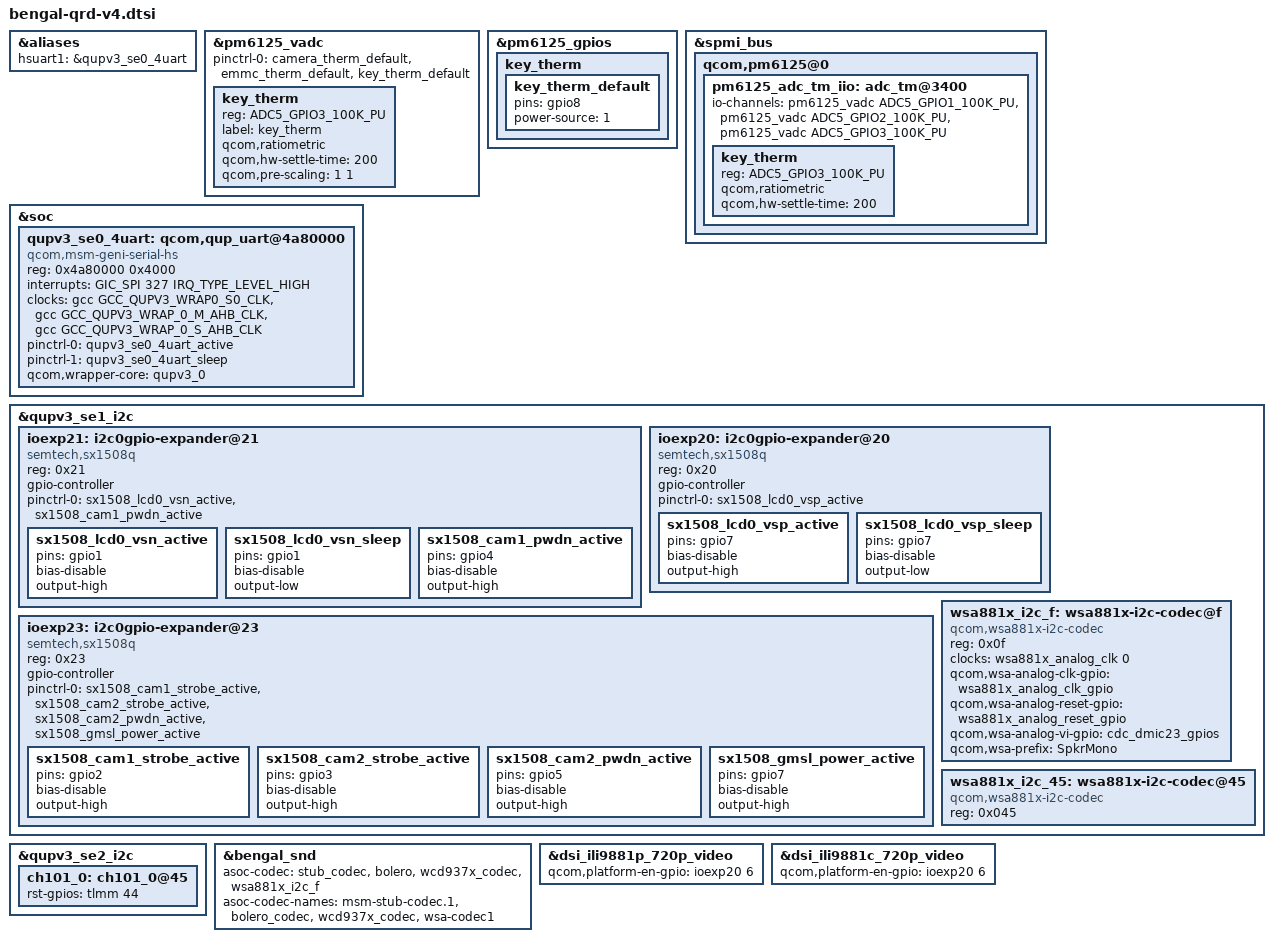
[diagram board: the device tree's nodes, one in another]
// SPDX-License-Identifier: BSD-3-Clause
/*
 * Copyright (c) Qualcomm Technologies, Inc. and/or its subsidiaries.
 */

#include "bengal-qrd-v3.dtsi"

&aliases {
	hsuart1 = &qupv3_se0_4uart;
};

&pm6125_vadc {
	pinctrl-0 = <&camera_therm_default &emmc_therm_default &key_therm_default>;

	key_therm {
		reg = <ADC5_GPIO3_100K_PU>;
		label = "key_therm";
		qcom,ratiometric;
		qcom,hw-settle-time = <200>;
		qcom,pre-scaling = <1 1>;
	};
};

&pm6125_gpios {
	key_therm {
		key_therm_default: key_therm_default {
			pins = "gpio8";
			power-source = <1>;
		};
	};

};

&spmi_bus {
	qcom,pm6125@0 {
		pm6125_adc_tm_iio: adc_tm@3400 {
			/delete-property/ io-channels;
			io-channels = <&pm6125_vadc ADC5_GPIO1_100K_PU>,
					<&pm6125_vadc ADC5_GPIO2_100K_PU>,
					<&pm6125_vadc ADC5_GPIO3_100K_PU>;

			key_therm {
				reg = <ADC5_GPIO3_100K_PU>;
				qcom,ratiometric;
				qcom,hw-settle-time = <200>;
			};
		};
	};
};

&soc {
	/delete-node/ i2c@4a80000;

	qupv3_se0_4uart: qcom,qup_uart@4a80000 {
		compatible = "qcom,msm-geni-serial-hs";
		reg = <0x4a80000 0x4000>;
		reg-names = "se_phys";
		interrupts = <GIC_SPI 327 IRQ_TYPE_LEVEL_HIGH>;
		clock-names = "se-clk", "m-ahb", "s-ahb";
		clocks = <&gcc GCC_QUPV3_WRAP0_S0_CLK>,
			<&gcc GCC_QUPV3_WRAP_0_M_AHB_CLK>,
			<&gcc GCC_QUPV3_WRAP_0_S_AHB_CLK>;
		pinctrl-names = "default", "sleep";
		pinctrl-0 = <&qupv3_se0_4uart_active>;
		pinctrl-1 = <&qupv3_se0_4uart_sleep>;
		qcom,wrapper-core = <&qupv3_0>;
		status = "ok";
	};
};

&qupv3_se1_i2c {
	status = "ok";

	ioexp21: i2c0gpio-expander@21 {
		#gpio-cells = <2>;
		compatible = "semtech,sx1508q";
		reg = <0x21>;
		gpio-controller;

		pinctrl-names = "default";
		pinctrl-0 = <&sx1508_lcd0_vsn_active
				&sx1508_cam1_pwdn_active>;

		sx1508_lcd0_vsn_active: sx1508_lcd0_vsn_active {
			pins = "gpio1";
			bias-disable;
			output-high;
		};

		sx1508_lcd0_vsn_sleep: sx1508_lcd0_vsn_sleep {
			pins = "gpio1";
			bias-disable;
			output-low;
		};

		sx1508_cam1_pwdn_active: sx1508_cam1_pwdn_active {
			pins = "gpio4";
			bias-disable;
			output-high;
		};
	};

	ioexp20: i2c0gpio-expander@20 {
		#gpio-cells = <2>;
		compatible = "semtech,sx1508q";
		reg = <0x20>;
		gpio-controller;

		pinctrl-names = "default";
		pinctrl-0 = <&sx1508_lcd0_vsp_active>;

		sx1508_lcd0_vsp_active: sx1508_lcd0_vsp_active {
			pins = "gpio7";
			bias-disable;
			output-high;
		};

		sx1508_lcd0_vsp_sleep: sx1508_lcd0_vsp_sleep {
			pins = "gpio7";
			bias-disable;
			output-low;
		};
	};

	ioexp23: i2c0gpio-expander@23 {
		#gpio-cells = <2>;
		compatible = "semtech,sx1508q";
		reg = <0x23>;
		gpio-controller;

		pinctrl-names = "default";
		pinctrl-0 = <&sx1508_cam1_strobe_active
				&sx1508_cam2_strobe_active
				&sx1508_cam2_pwdn_active
				&sx1508_gmsl_power_active>;

		sx1508_cam1_strobe_active: sx1508_cam1_strobe_active {
			pins = "gpio2";
			bias-disable;
			output-high;
		};

		sx1508_cam2_strobe_active: sx1508_cam2_strobe_active {
			pins = "gpio3";
			bias-disable;
			output-high;
		};

		sx1508_cam2_pwdn_active: sx1508_cam2_pwdn_active {
			pins = "gpio5";
			bias-disable;
			output-high;
		};

		sx1508_gmsl_power_active: sx1508_gmsl_power_active {
			pins = "gpio7";
			bias-disable;
			output-high;
		};
	};
};

&qupv3_se2_i2c {
	ch101_0: ch101_0@45 {
		/delete-property/ rst-gpios;
		rst-gpios = <&tlmm 44 GPIO_ACTIVE_HIGH>;
	};
};

&bengal_snd {
	/delete-property/ asoc-codec;
	/delete-property/ asoc-codec-names;
	asoc-codec  = <&stub_codec>, <&bolero>,
			<&wcd937x_codec>, <&wsa881x_i2c_f>;
	asoc-codec-names = "msm-stub-codec.1", "bolero_codec",
		"wcd937x_codec", "wsa-codec1";

};

&qupv3_se1_i2c {
	/delete-node/ wsa881x-i2c-codec@e;
	wsa881x_i2c_f: wsa881x-i2c-codec@f {
		compatible = "qcom,wsa881x-i2c-codec";
		reg = <0x0f>;
		clock-names = "wsa_mclk";
		clocks = <&wsa881x_analog_clk 0>;
		qcom,wsa-analog-clk-gpio = <&wsa881x_analog_clk_gpio>;
		qcom,wsa-analog-reset-gpio = <&wsa881x_analog_reset_gpio>;
		qcom,wsa-analog-vi-gpio = <&cdc_dmic23_gpios>;
		qcom,wsa-prefix = "SpkrMono";
	};

	/delete-node/ wsa881x-i2c-codec@44;
	wsa881x_i2c_45: wsa881x-i2c-codec@45 {
		compatible = "qcom,wsa881x-i2c-codec";
		reg = <0x045>;
	};
};

&dsi_ili9881p_720p_video {
	/delete-property/ qcom,platform-en-gpio;
	qcom,platform-en-gpio = <&ioexp20 6 0>;
};

&dsi_ili9881c_720p_video {
	/delete-property/ qcom,platform-en-gpio;
	qcom,platform-en-gpio = <&ioexp20 6 0>;
};
